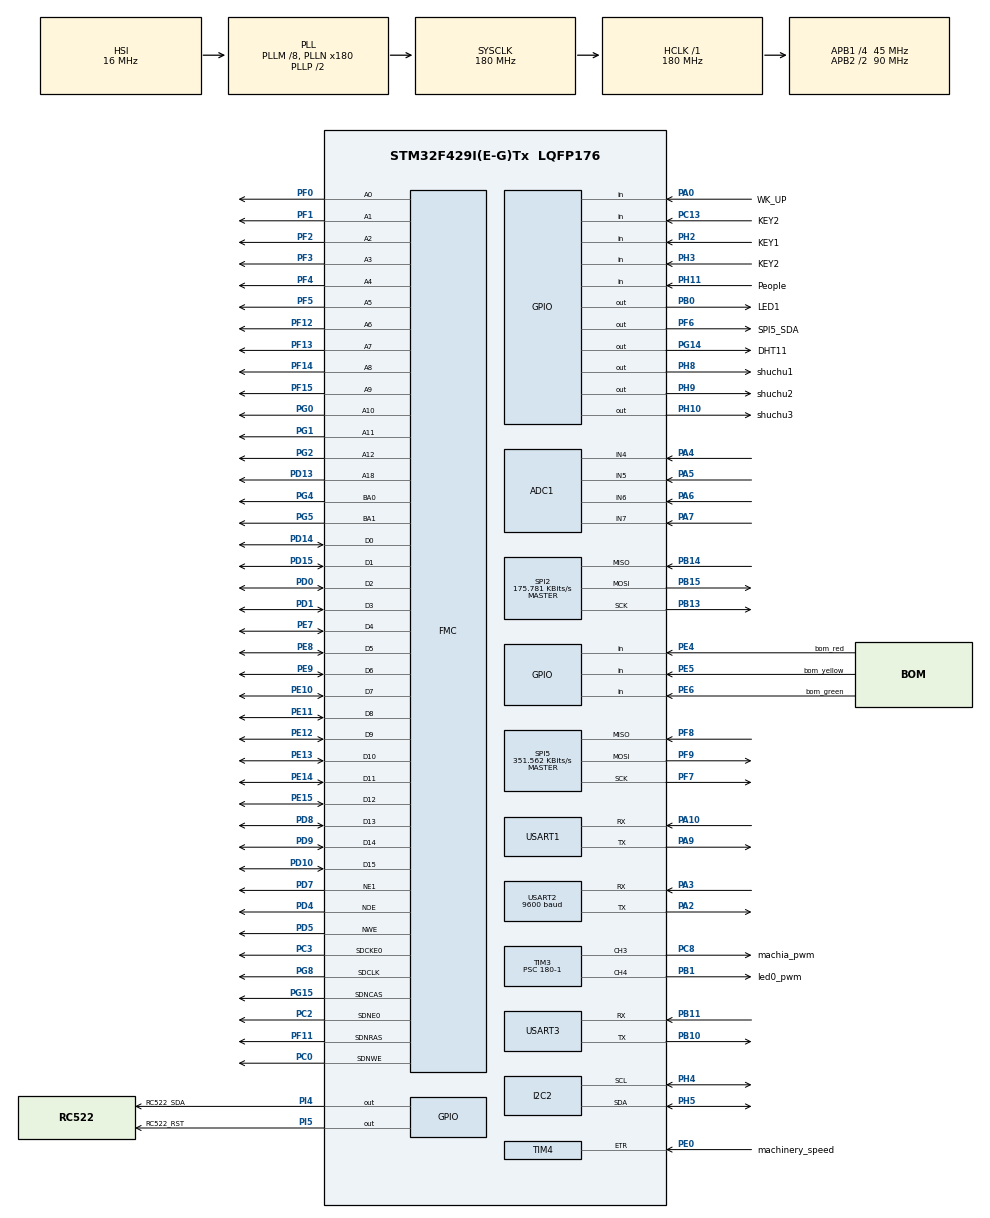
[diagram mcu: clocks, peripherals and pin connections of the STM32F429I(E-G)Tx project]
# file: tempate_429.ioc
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ADC1.Channel-0\#ChannelRegularConversion=ADC_CHANNEL_4
ADC1.Channel-1\#ChannelRegularConversion=ADC_CHANNEL_5
ADC1.Channel-2\#ChannelRegularConversion=ADC_CHANNEL_6
ADC1.Channel-3\#ChannelRegularConversion=ADC_CHANNEL_7
ADC1.ContinuousConvMode=ENABLE
ADC1.DMAContinuousRequests=ENABLE
ADC1.NbrOfConversion=4
ADC1.NbrOfConversionFlag=1
ADC1.Rank-0\#ChannelRegularConversion=1
ADC1.Rank-1\#ChannelRegularConversion=2
ADC1.Rank-2\#ChannelRegularConversion=3
ADC1.Rank-3\#ChannelRegularConversion=4
ADC1.SamplingTime-0\#ChannelRegularConversion=ADC_SAMPLETIME_15CYCLES
ADC1.SamplingTime-1\#ChannelRegularConversion=ADC_SAMPLETIME_15CYCLES
ADC1.SamplingTime-2\#ChannelRegularConversion=ADC_SAMPLETIME_15CYCLES
ADC1.SamplingTime-3\#ChannelRegularConversion=ADC_SAMPLETIME_15CYCLES
ADC1.ScanConvMode=ENABLE
ADC1.master=1
Dma.ADC1.0.Direction=DMA_PERIPH_TO_MEMORY
Dma.ADC1.0.FIFOMode=DMA_FIFOMODE_DISABLE
Dma.ADC1.0.Instance=DMA2_Stream0
Dma.ADC1.0.MemDataAlignment=DMA_MDATAALIGN_WORD
Dma.ADC1.0.MemInc=DMA_MINC_ENABLE
Dma.ADC1.0.Mode=DMA_CIRCULAR
Dma.ADC1.0.PeriphDataAlignment=DMA_PDATAALIGN_WORD
Dma.ADC1.0.PeriphInc=DMA_PINC_DISABLE
Dma.ADC1.0.Priority=DMA_PRIORITY_LOW
Dma.Request0=ADC1
Dma.Request1=USART3_RX
Dma.USART3_RX.1.Direction=DMA_PERIPH_TO_MEMORY
Dma.USART3_RX.1.FIFOMode=DMA_FIFOMODE_DISABLE
Dma.USART3_RX.1.Instance=DMA1_Stream1
Dma.USART3_RX.1.MemDataAlignment=DMA_MDATAALIGN_BYTE
Dma.USART3_RX.1.MemInc=DMA_MINC_ENABLE
Dma.USART3_RX.1.Mode=DMA_NORMAL
Dma.USART3_RX.1.PeriphDataAlignment=DMA_PDATAALIGN_BYTE
Dma.USART3_RX.1.PeriphInc=DMA_PINC_DISABLE
Dma.USART3_RX.1.Priority=DMA_PRIORITY_LOW
FMC.BusTurnAroundDuration1=1
FMC.CASLatency1=FMC_SDRAM_CAS_LATENCY_3
FMC.ColumnBitsNumber1=FMC_SDRAM_COLUMN_BITS_NUM_9
FMC.DataSetupTime1=46
FMC.ExitSelfRefreshDelay1=8
FMC.ExtendedBusTurnAroundDuration1=1
FMC.ExtendedDataSetupTime1=15
FMC.ExtendedMode1=FMC_EXTENDED_MODE_ENABLE
FMC.LoadToActiveDelay1=2
FMC.RCDDelay1=2
FMC.RPDelay1=2
FMC.RPDelay2=2
FMC.ReadBurst1=FMC_SDRAM_RBURST_ENABLE
FMC.ReadBurst2=FMC_SDRAM_RBURST_ENABLE
FMC.ReadPipeDelay1=FMC_SDRAM_RPIPE_DELAY_1
FMC.ReadPipeDelay2=FMC_SDRAM_RPIPE_DELAY_1
FMC.RowCycleDelay1=6
FMC.RowCycleDelay2=6
FMC.SDClockPeriod1=FMC_SDRAM_CLOCK_PERIOD_2
FMC.SDClockPeriod2=FMC_SDRAM_CLOCK_PERIOD_2
FMC.SelfRefreshTime1=6
FMC.WriteRecoveryTime1=4
Mcu.Family=STM32F4
Mcu.Name=STM32F429I(E-G)Tx
Mcu.Package=LQFP176
NVIC.DMA1_Stream1_IRQn=true\:0\:0\:false\:false\:true\:false\:false\:true\:true
NVIC.DMA2_Stream0_IRQn=true\:0\:0\:false\:false\:true\:false\:false\:true\:true
NVIC.PriorityGroup=NVIC_PRIORITYGROUP_2
NVIC.TIM1_UP_TIM10_IRQn=true\:3\:0\:true\:false\:true\:false\:true\:true\:true
NVIC.TIM2_IRQn=true\:3\:0\:true\:false\:true\:false\:true\:true\:true
NVIC.TIM8_TRG_COM_TIM14_IRQn=true\:3\:0\:false\:false\:true\:false\:false\:true\:true
NVIC.TimeBase=TIM8_TRG_COM_TIM14_IRQn
NVIC.TimeBaseIP=TIM14
NVIC.USART3_IRQn=true\:0\:0\:false\:false\:true\:false\:true\:true\:true
PA0/WKUP.GPIO_Label=WK_UP
PA0/WKUP.GPIO_PuPd=GPIO_PULLDOWN
PA0/WKUP.Signal=GPIO_Input
PA10.Mode=Asynchronous
PA10.Signal=USART1_RX
PA13.Mode=Serial_Wire
PA13.Signal=SYS_JTMS-SWDIO
PA14.Mode=Serial_Wire
PA14.Signal=SYS_JTCK-SWCLK
PA2.Mode=Asynchronous
PA2.Signal=USART2_TX
PA3.Mode=Asynchronous
PA3.Signal=USART2_RX
PA4.Signal=ADCx_IN4
PA5.Signal=ADCx_IN5
PA6.Signal=ADCx_IN6
PA7.Signal=ADCx_IN7
PA9.Mode=Asynchronous
PA9.Signal=USART1_TX
PB0.GPIO_Label=LED1
PB0.PinState=GPIO_PIN_SET
PB0.Signal=GPIO_Output
PB1.GPIO_Label=led0_pwm
PB1.Signal=S_TIM3_CH4
PB10.Mode=Asynchronous
PB10.Signal=USART3_TX
PB11.Mode=Asynchronous
PB11.Signal=USART3_RX
PB13.Mode=Full_Duplex_Master
PB13.Signal=SPI2_SCK
PB14.Mode=Full_Duplex_Master
PB14.Signal=SPI2_MISO
PB15.Mode=Full_Duplex_Master
PB15.Signal=SPI2_MOSI
PC0.Signal=FMC_SDNWE
PC13.GPIO_Label=KEY2
PC13.GPIO_PuPd=GPIO_PULLUP
PC13.Signal=GPIO_Input
PC14/OSC32_IN.Mode=LSE-External-Oscillator
PC14/OSC32_IN.Signal=RCC_OSC32_IN
PC15/OSC32_OUT.Mode=LSE-External-Oscillator
PC15/OSC32_OUT.Signal=RCC_OSC32_OUT
PC2.Mode=SdramChipSelect1_1
PC2.Signal=FMC_SDNE0
PC3.Mode=SdramChipSelect1_1
PC3.Signal=FMC_SDCKE0
PC8.GPIO_Label=machia_pwm
PC8.Signal=S_TIM3_CH3
PD0.Signal=FMC_D2_DA2
PD1.Signal=FMC_D3_DA3
PD10.Signal=FMC_D15_DA15
PD13.Signal=FMC_A18
PD14.Signal=FMC_D0_DA0
PD15.Signal=FMC_D1_DA1
PD4.Signal=FMC_NOE
PD5.Signal=FMC_NWE
PD7.Mode=NorPsramChipSelect1_1
PD7.Signal=FMC_NE1
PD8.Signal=FMC_D13_DA13
PD9.Signal=FMC_D14_DA14
PE0.GPIO_Label=machinery_speed
PE0.Signal=S_TIM4_ETR
PE10.Signal=FMC_D7_DA7
PE11.Signal=FMC_D8_DA8
PE12.Signal=FMC_D9_DA9
PE13.Signal=FMC_D10_DA10
PE14.Signal=FMC_D11_DA11
PE15.Signal=FMC_D12_DA12
PE4.GPIO_Label=bom_red
PE4.GPIO_PuPd=GPIO_PULLUP
PE4.Signal=GPIO_Input
PE5.GPIO_Label=bom_yellow
PE5.GPIO_PuPd=GPIO_PULLUP
PE5.Signal=GPIO_Input
PE6.GPIO_Label=bom_green
PE6.GPIO_PuPd=GPIO_PULLUP
PE6.Signal=GPIO_Input
PE7.Signal=FMC_D4_DA4
PE8.Signal=FMC_D5_DA5
PE9.Signal=FMC_D6_DA6
PF0.Signal=FMC_A0
PF1.Signal=FMC_A1
PF11.Signal=FMC_SDNRAS
PF12.Signal=FMC_A6
PF13.Signal=FMC_A7
PF14.Signal=FMC_A8
PF15.Signal=FMC_A9
PF2.Signal=FMC_A2
PF3.Signal=FMC_A3
PF4.Signal=FMC_A4
PF5.Signal=FMC_A5
PF6.GPIO_Label=SPI5_SDA
PF6.GPIO_PuPd=GPIO_PULLUP
PF6.GPIO_Speed=GPIO_SPEED_FREQ_VERY_HIGH
PF6.PinState=GPIO_PIN_SET
PF6.Signal=GPIO_Output
PF7.Mode=Full_Duplex_Master
PF7.Signal=SPI5_SCK
PF8.Mode=Full_Duplex_Master
PF8.Signal=SPI5_MISO
PF9.Mode=Full_Duplex_Master
PF9.Signal=SPI5_MOSI
PG0.Signal=FMC_A10
PG1.Signal=FMC_A11
PG14.GPIO_Label=DHT11
PG14.Signal=GPIO_Output
PG15.Signal=FMC_SDNCAS
PG2.Signal=FMC_A12
PG4.Signal=FMC_A14_BA0
PG5.Signal=FMC_A15_BA1
PG8.Signal=FMC_SDCLK
PH0/OSC_IN.Mode=HSE-External-Oscillator
PH0/OSC_IN.Signal=RCC_OSC_IN
PH1/OSC_OUT.Mode=HSE-External-Oscillator
PH1/OSC_OUT.Signal=RCC_OSC_OUT
PH10.GPIO_Label=shuchu3
PH10.Signal=GPIO_Output
PH11.GPIO_Label=People
PH11.Signal=GPIO_Input
PH2.GPIO_Label=KEY1
PH2.GPIO_PuPd=GPIO_PULLUP
PH2.Signal=GPIO_Input
PH3.GPIO_Label=KEY2
PH3.GPIO_PuPd=GPIO_PULLUP
PH3.Signal=GPIO_Input
PH4.Mode=I2C
PH4.Signal=I2C2_SCL
PH5.Mode=I2C
PH5.Signal=I2C2_SDA
PH8.GPIO_Label=shuchu1
PH8.Signal=GPIO_Output
PH9.GPIO_Label=shuchu2
PH9.Signal=GPIO_Output
PI4.GPIO_Label=RC522_SDA
PI4.Signal=GPIO_Output
PI5.GPIO_Label=RC522_RST
PI5.Signal=GPIO_Output
ProjectManager.HeapSize=0xF00
ProjectManager.StackSize=0xF00
ProjectManager.TargetToolchain=MDK-ARM V5.32
RCC.48MHZClocksFreq_Value=90000000
RCC.AHBFreq_Value=180000000
RCC.APB1CLKDivider=RCC_HCLK_DIV4
RCC.APB1Freq_Value=45000000
RCC.APB1TimFreq_Value=90000000
RCC.APB2CLKDivider=RCC_HCLK_DIV2
RCC.APB2Freq_Value=90000000
RCC.APB2TimFreq_Value=180000000
RCC.CortexFreq_Value=180000000
RCC.HCLKFreq_Value=180000000
RCC.HSE_VALUE=25000000
RCC.HSI_VALUE=16000000
RCC.PLLM=8
RCC.PLLN=180
RCC.SYSCLKFreq_VALUE=180000000
RCC.SYSCLKSource=RCC_SYSCLKSOURCE_PLLCLK
RCC.VCOOutputFreq_Value=360000000
RealThread.RT-Thread.3.1.5.RTOSJjkernel=true
RealThread.RT-Thread.3.1.5.RT_MAIN_THREAD_STACK_SIZE=2048
RealThread.RT-Thread.3.1.5.RT_USING_HEAP=1
RealThread.RT-Thread.3.1.5.RT_USING_MUTEX=1
RealThread.RT-Thread.3.1.5.RT_USING_USER_MAIN=1
SH.ADCx_IN4.0=ADC1_IN4,IN4
SH.ADCx_IN5.0=ADC1_IN5,IN5
SH.ADCx_IN6.0=ADC1_IN6,IN6
SH.ADCx_IN7.0=ADC1_IN7,IN7
SH.FMC_A0.0=FMC_A0,13b-sda1
SH.FMC_A1.0=FMC_A1,13b-sda1
SH.FMC_A10.0=FMC_A10,13b-sda1
SH.FMC_A11.0=FMC_A11,13b-sda1
SH.FMC_A12.0=FMC_A12,13b-sda1
SH.FMC_A14_BA0.0=FMC_BA0,FourSdramBanks1
SH.FMC_A15_BA1.0=FMC_BA1,FourSdramBanks1
SH.FMC_A18.0=FMC_A18,A18_1
SH.FMC_A2.0=FMC_A2,13b-sda1
SH.FMC_A3.0=FMC_A3,13b-sda1
SH.FMC_A4.0=FMC_A4,13b-sda1
SH.FMC_A5.0=FMC_A5,13b-sda1
SH.FMC_A6.0=FMC_A6,13b-sda1
SH.FMC_A7.0=FMC_A7,13b-sda1
SH.FMC_A8.0=FMC_A8,13b-sda1
SH.FMC_A9.0=FMC_A9,13b-sda1
SH.FMC_D0_DA0.0=FMC_D0,16b-d1
SH.FMC_D0_DA0.1=FMC_D0,sd-16b-d1
SH.FMC_D10_DA10.0=FMC_D10,16b-d1
SH.FMC_D10_DA10.1=FMC_D10,sd-16b-d1
SH.FMC_D11_DA11.0=FMC_D11,16b-d1
SH.FMC_D11_DA11.1=FMC_D11,sd-16b-d1
SH.FMC_D12_DA12.0=FMC_D12,16b-d1
SH.FMC_D12_DA12.1=FMC_D12,sd-16b-d1
SH.FMC_D13_DA13.0=FMC_D13,16b-d1
SH.FMC_D13_DA13.1=FMC_D13,sd-16b-d1
SH.FMC_D14_DA14.0=FMC_D14,16b-d1
SH.FMC_D14_DA14.1=FMC_D14,sd-16b-d1
SH.FMC_D15_DA15.0=FMC_D15,16b-d1
SH.FMC_D15_DA15.1=FMC_D15,sd-16b-d1
SH.FMC_D1_DA1.0=FMC_D1,16b-d1
SH.FMC_D1_DA1.1=FMC_D1,sd-16b-d1
SH.FMC_D2_DA2.0=FMC_D2,16b-d1
SH.FMC_D2_DA2.1=FMC_D2,sd-16b-d1
SH.FMC_D3_DA3.0=FMC_D3,16b-d1
SH.FMC_D3_DA3.1=FMC_D3,sd-16b-d1
SH.FMC_D4_DA4.0=FMC_D4,16b-d1
SH.FMC_D4_DA4.1=FMC_D4,sd-16b-d1
SH.FMC_D5_DA5.0=FMC_D5,16b-d1
SH.FMC_D5_DA5.1=FMC_D5,sd-16b-d1
SH.FMC_D6_DA6.0=FMC_D6,16b-d1
SH.FMC_D6_DA6.1=FMC_D6,sd-16b-d1
SH.FMC_D7_DA7.0=FMC_D7,16b-d1
SH.FMC_D7_DA7.1=FMC_D7,sd-16b-d1
SH.FMC_D8_DA8.0=FMC_D8,16b-d1
SH.FMC_D8_DA8.1=FMC_D8,sd-16b-d1
SH.FMC_D9_DA9.0=FMC_D9,16b-d1
SH.FMC_D9_DA9.1=FMC_D9,sd-16b-d1
SH.FMC_NOE.0=FMC_NOE,Lcd1
SH.FMC_NWE.0=FMC_NWE,Lcd1
SH.FMC_SDCLK.0=FMC_SDCLK,13b-sda1
SH.FMC_SDNCAS.0=FMC_SDNCAS,13b-sda1
SH.FMC_SDNRAS.0=FMC_SDNRAS,13b-sda1
SH.FMC_SDNWE.0=FMC_SDNWE,13b-sda1
SH.S_TIM3_CH3.0=TIM3_CH3,PWM Generation3 CH3
SH.S_TIM3_CH4.0=TIM3_CH4,PWM Generation4 CH4
SH.S_TIM4_ETR.0=TIM4_ETR,ClockSourceETR_Mode2
SPI2.BaudRatePrescaler=SPI_BAUDRATEPRESCALER_256
SPI2.CalculateBaudRate=175.781 KBits/s
SPI2.Direction=SPI_DIRECTION_2LINES
SPI2.Mode=SPI_MODE_MASTER
SPI2.VirtualType=VM_MASTER
SPI5.BaudRatePrescaler=SPI_BAUDRATEPRESCALER_256
SPI5.CLKPhase=SPI_PHASE_2EDGE
SPI5.CLKPolarity=SPI_POLARITY_HIGH
SPI5.CalculateBaudRate=351.562 KBits/s
SPI5.Direction=SPI_DIRECTION_2LINES
SPI5.Mode=SPI_MODE_MASTER
SPI5.VirtualType=VM_MASTER
TIM1.AutoReloadPreload=TIM_AUTORELOAD_PRELOAD_ENABLE
TIM1.Period=10000-1
TIM1.Prescaler=18000-1
TIM2.AutoReloadPreload=TIM_AUTORELOAD_PRELOAD_ENABLE
TIM2.Period=1000-1
TIM2.Prescaler=18000-1
TIM3.AutoReloadPreload=TIM_AUTORELOAD_PRELOAD_ENABLE
TIM3.Channel-PWM\ Generation3\ CH3=TIM_CHANNEL_3
TIM3.Channel-PWM\ Generation4\ CH4=TIM_CHANNEL_4
TIM3.Period=500-1
TIM3.Prescaler=180-1
TIM3.Pulse-PWM\ Generation3\ CH3=499
TIM3.Pulse-PWM\ Generation4\ CH4=499
USART1.VirtualMode=VM_ASYNC
USART2.BaudRate=9600
USART2.VirtualMode=VM_ASYNC
USART3.VirtualMode=VM_ASYNC
VP_RealThread.RT-Thread_VS_RTOSJjkernel_3.1.5_3.1.5.Mode=RTOSJjkernel
VP_SYS_VS_tim14.Mode=TIM14
VP_TIM1_VS_ClockSourceINT.Mode=Internal
VP_TIM2_VS_ClockSourceINT.Mode=Internal
VP_TIM3_VS_ClockSourceINT.Mode=Internal
board=custom

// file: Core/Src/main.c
/* USER CODE BEGIN Header */
/**
  ******************************************************************************
  * @file           : main.c
  * @brief          : Main program body
  ******************************************************************************
  * @attention
  *
  * Copyright (c) 2023 STMicroelectronics.
  * All rights reserved.
  *
  * This software is licensed under terms that can be found in the LICENSE file
  * in the root directory of this software component.
  * If no LICENSE file comes with this software, it is provided AS-IS.
  *
  ******************************************************************************
  */
/* USER CODE END Header */
#include "main.h"
#include "adc.h"
#include "dma.h"
#include "i2c.h"
#include "spi.h"
#include "tim.h"
#include "usart.h"
#include "gpio.h"
#include "fmc.h"

void SystemClock_Config(void);

/* USER CODE BEGIN 0 */

rt_thread_t sensor_thread_id;   // 读取传感器的线程
rt_thread_t logical_thread_id;   // 逻辑线程
rt_thread_t showlcd_thread_id;   // 显示线程
rt_mutex_t mutex1;    			// 线程锁
rt_thread_t Rfid_thread_id;    // 读rfid
rt_thread_t key_thread_id;    // 按键检测
rt_thread_t ping_thread_id;   // 保活线程

/* USER CODE END 0 */

int main(void)
{
  /* USER CODE BEGIN 1 */
    uint16_t timeCount = 0;
    unsigned char *dataPtr = NULL;
  /* USER CODE END 1 */

  /* MCU Configuration--------------------------------------------------------*/

  /* Reset of all peripherals, Initializes the Flash interface and the Systick. */
  HAL_Init();

  /* Configure the system clock */
  SystemClock_Config();

  /* Initialize all configured peripherals */
  MX_GPIO_Init();
  MX_DMA_Init();
  MX_ADC1_Init();
  MX_I2C2_Init();
  MX_SPI2_Init();
  MX_TIM1_Init();
  MX_TIM2_Init();
  MX_USART1_UART_Init();
  MX_USART3_UART_Init();
  MX_FMC_Init();
  MX_TIM3_Init();
  MX_USART2_UART_Init();
  MX_TIM4_Init();
  MX_SPI5_Init();
  /* USER CODE BEGIN 2 */

	Mx_Init();

	mutex1 = rt_mutex_create("mutex1",RT_IPC_FLAG_PRIO);

	// 显示线程
	showlcd_thread_id = rt_thread_create("showlcd_thread",lcd_show,NULL,1024,11,50);
	if(showlcd_thread_id!=RT_NULL){
		rt_thread_startup(showlcd_thread_id);
		printf("线程 showlcd_thread_id 创建成功\r\n");
	}

	// 传感器线程
	sensor_thread_id = rt_thread_create("sensor_thread",collect_data,NULL,512,11,30);
	if(sensor_thread_id!=RT_NULL){
		rt_thread_startup(sensor_thread_id);
		printf("线程 sensor_thread_id 创建成功\r\n");
	}

	// 读rfid
	Rfid_thread_id = rt_thread_create("rfid_thread",read_rfid,NULL,1024,12,30);
	if(Rfid_thread_id!=RT_NULL){
	rt_thread_startup(Rfid_thread_id);
	printf("线程 Rfid_thread_id 创建成功\r\n");
	}

	// 逻辑线程
	logical_thread_id = rt_thread_create("logical_thread",Logical_code_entry,NULL,512,11,20);
	if(logical_thread_id!=RT_NULL){
		rt_thread_startup(logical_thread_id);
		printf("线程 logical_thread_id 创建成功\r\n");
	}

	// 按键的扫描线程
	key_thread_id = rt_thread_create("key_thread",key_thread_entry,RT_NULL,512,12,30);
	if(key_thread_id!=RT_NULL){
		rt_thread_startup(key_thread_id);
		printf("线程 key_thread_id 创建成功\r\n");
	}

	// 保活线程
	ping_thread_id = rt_thread_create("ping_thread",ping_thread_entry,RT_NULL,512,2,20);
	if(key_thread_id!=RT_NULL){
		rt_thread_startup(ping_thread_id);
		printf("线程 ping_thread_id 创建成功\r\n");
	}
  /* USER CODE END 2 */

  /* Infinite loop */
  /* USER CODE BEGIN WHILE */
  while (1)
  {
	  if(net_connect == 1)
	  {

            ++timeCount;

            if(timeCount >= 200)		//时间间隔5s 发送
            {

				// 判断是否有时间同步
				if(time_flag==0)
				{
					OneNet_Send_Device_ID_Data();
				}
//              rt_thread_mdelay(100);
                printf( "开始发送数据\r\n");//通过串口1发送提示信息（要开始发送数据了）
                OneNet_SendData(0);//发送数据给onenet
                printf("发送数据结束\n");
                //				while(OneNet_DevLink())			//接入OneNET
                timeCount = 0;
                ESP8266_Clear();
            }
            dataPtr = ESP8266_GetIPD(0);//获取平台返回的数据
            if(dataPtr != NULL)//如果返回数据不为空
			{
                OneNet_RevPro(dataPtr);//平台返回数据检测
//				timeCount = 0;

			}
            rt_thread_mdelay(40);
	  }
	  else if(net_connect == 2||net_connect==3)
	  {
		  rt_thread_mdelay(200);
		  if(net_connect==2)
		  {
			resest_wifi();
		  }
		  if(net_connect==3)
		  {
			resest_server();
		  }
	  }
    /* USER CODE END WHILE */

    /* USER CODE BEGIN 3 */
	  else
	  {
			printf("开始连接服务器\r\n");
            ESP8266_Init();					//初始化ESP8266

            printf("8266初始化成功\n");

            while(OneNet_DevLink())			//接入OneNET

			rt_thread_mdelay(200);
            net_connect = 1;
//            HAL_ADC_Start_DMA(&hadc1, (uint32_t *)adc_value, 40);

            printf("接入onenet成功");

	  }
  }
  /* USER CODE END 3 */
}

void SystemClock_Config(void)
{
  RCC_OscInitTypeDef RCC_OscInitStruct = {0};
  RCC_ClkInitTypeDef RCC_ClkInitStruct = {0};

  /** Configure the main internal regulator output voltage
  */
  __HAL_RCC_PWR_CLK_ENABLE();
  __HAL_PWR_VOLTAGESCALING_CONFIG(PWR_REGULATOR_VOLTAGE_SCALE1);

  /** Initializes the RCC Oscillators according to the specified parameters
  * in the RCC_OscInitTypeDef structure.
  */
  RCC_OscInitStruct.OscillatorType = RCC_OSCILLATORTYPE_HSI;
  RCC_OscInitStruct.HSIState = RCC_HSI_ON;
  RCC_OscInitStruct.HSICalibrationValue = RCC_HSICALIBRATION_DEFAULT;
  RCC_OscInitStruct.PLL.PLLState = RCC_PLL_ON;
  RCC_OscInitStruct.PLL.PLLSource = RCC_PLLSOURCE_HSI;
  RCC_OscInitStruct.PLL.PLLM = 8;
  RCC_OscInitStruct.PLL.PLLN = 180;
  RCC_OscInitStruct.PLL.PLLP = RCC_PLLP_DIV2;
  RCC_OscInitStruct.PLL.PLLQ = 4;
  if (HAL_RCC_OscConfig(&RCC_OscInitStruct) != HAL_OK)
  {
    Error_Handler();
  }

  /** Activate the Over-Drive mode
  */
  if (HAL_PWREx_EnableOverDrive() != HAL_OK)
  {
    Error_Handler();
  }

  /** Initializes the CPU, AHB and APB buses clocks
  */
  RCC_ClkInitStruct.ClockType = RCC_CLOCKTYPE_HCLK|RCC_CLOCKTYPE_SYSCLK
                              |RCC_CLOCKTYPE_PCLK1|RCC_CLOCKTYPE_PCLK2;
  RCC_ClkInitStruct.SYSCLKSource = RCC_SYSCLKSOURCE_PLLCLK;
  RCC_ClkInitStruct.AHBCLKDivider = RCC_SYSCLK_DIV1;
  RCC_ClkInitStruct.APB1CLKDivider = RCC_HCLK_DIV4;
  RCC_ClkInitStruct.APB2CLKDivider = RCC_HCLK_DIV2;

  if (HAL_RCC_ClockConfig(&RCC_ClkInitStruct, FLASH_LATENCY_5) != HAL_OK)
  {
    Error_Handler();
  }
}

void HAL_TIM_PeriodElapsedCallback(TIM_HandleTypeDef *htim)
{
  if (htim->Instance == TIM14) {
    HAL_IncTick();
  }
}

void Error_Handler(void)
{
  __disable_irq();
  while (1)
  {
  }
}
